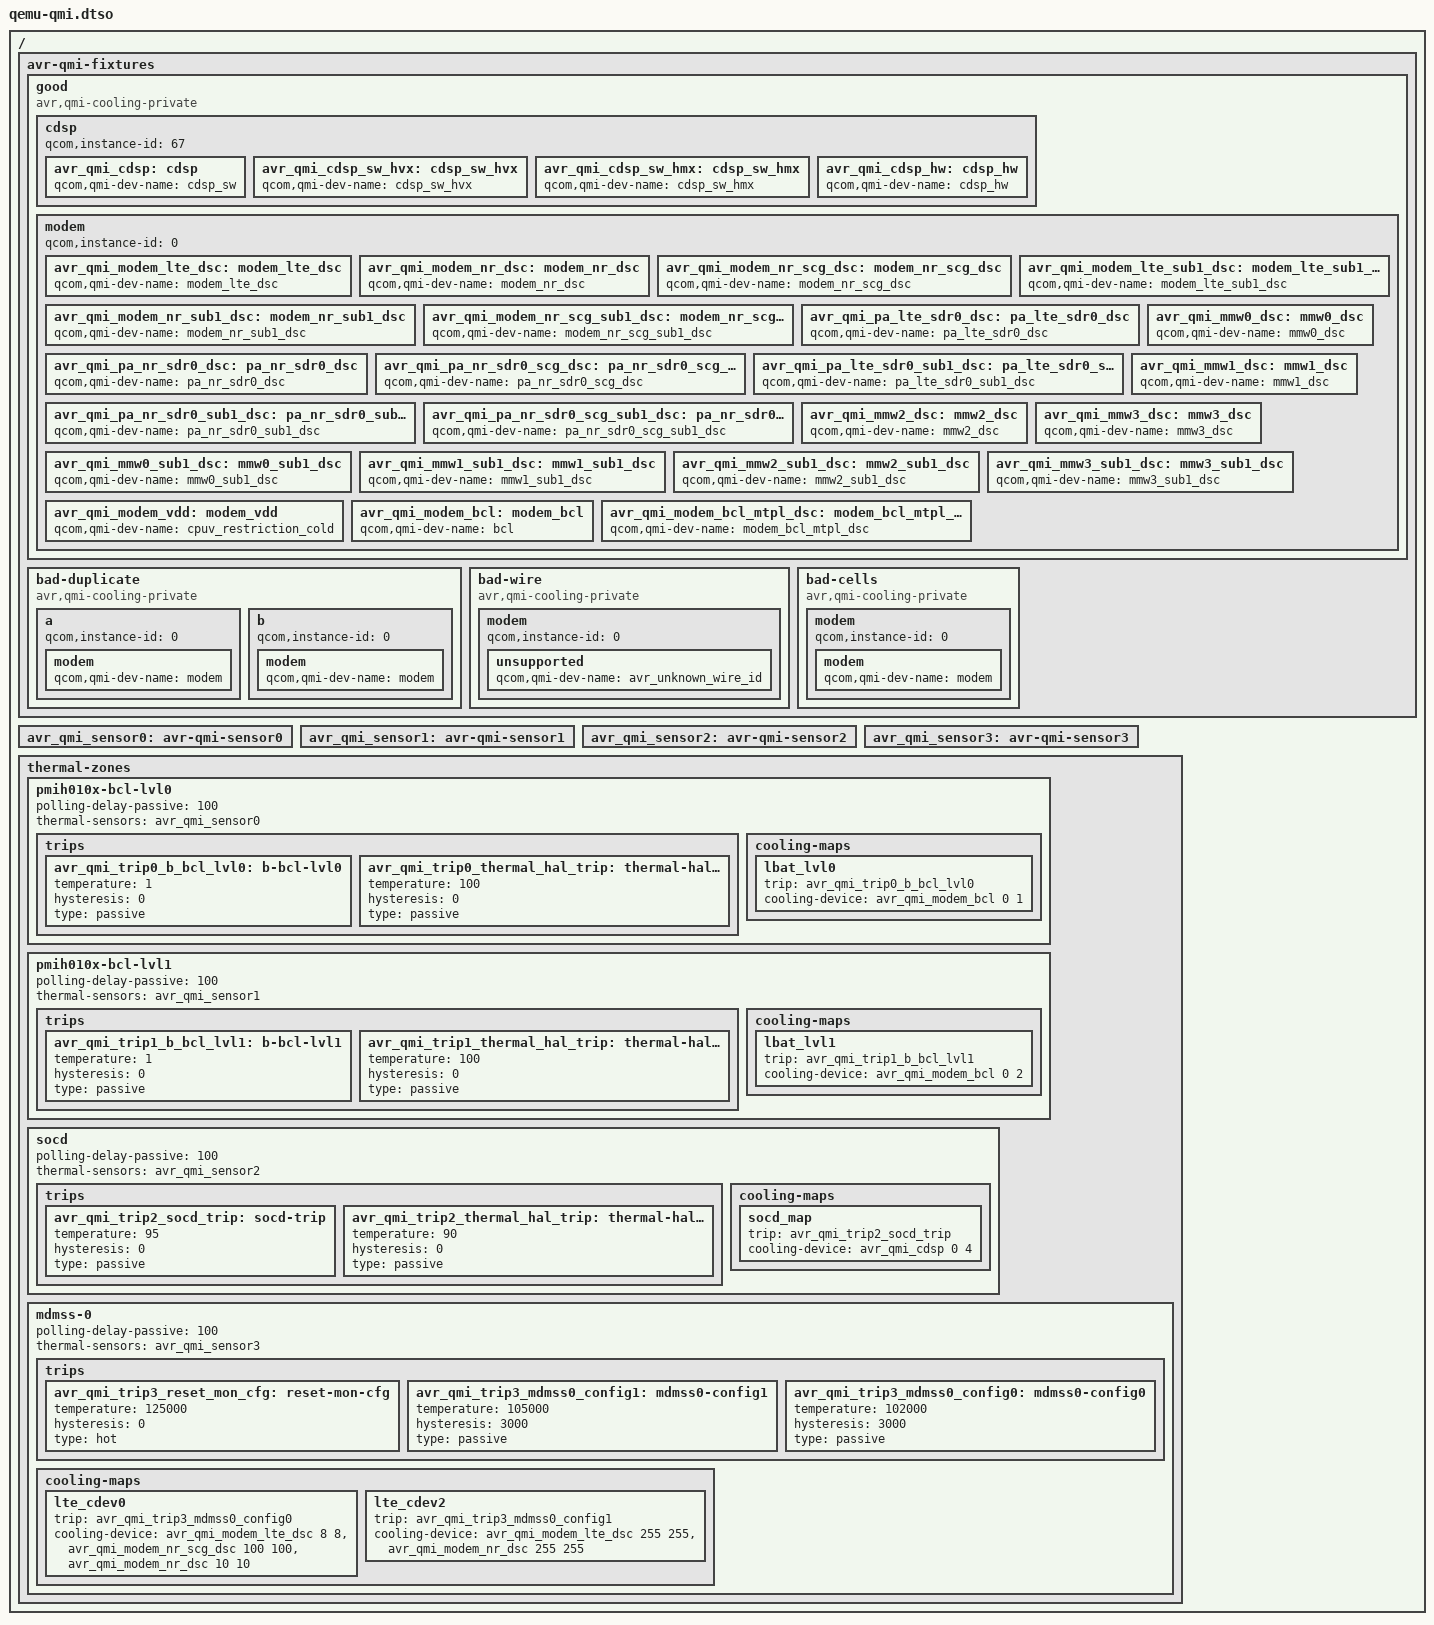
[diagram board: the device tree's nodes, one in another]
/dts-v1/;
/plugin/;
/* Private QEMU nodes; saved AVR instance IDs, names and cooling arity. */
/ { fragment@0 { target-path = "/"; __overlay__ { avr-qmi-fixtures {
 good { compatible = "avr,qmi-cooling-private";
 cdsp { qcom,instance-id = <67>;
  avr_qmi_cdsp: cdsp { qcom,qmi-dev-name = "cdsp_sw"; #cooling-cells = <2>; };
  avr_qmi_cdsp_sw_hvx: cdsp_sw_hvx { qcom,qmi-dev-name = "cdsp_sw_hvx"; #cooling-cells = <2>; };
  avr_qmi_cdsp_sw_hmx: cdsp_sw_hmx { qcom,qmi-dev-name = "cdsp_sw_hmx"; #cooling-cells = <2>; };
  avr_qmi_cdsp_hw: cdsp_hw { qcom,qmi-dev-name = "cdsp_hw"; #cooling-cells = <2>; };
 };
 modem { qcom,instance-id = <0>;
  avr_qmi_modem_lte_dsc: modem_lte_dsc { qcom,qmi-dev-name = "modem_lte_dsc"; #cooling-cells = <2>; };
  avr_qmi_modem_nr_dsc: modem_nr_dsc { qcom,qmi-dev-name = "modem_nr_dsc"; #cooling-cells = <2>; };
  avr_qmi_modem_nr_scg_dsc: modem_nr_scg_dsc { qcom,qmi-dev-name = "modem_nr_scg_dsc"; #cooling-cells = <2>; };
  avr_qmi_modem_lte_sub1_dsc: modem_lte_sub1_dsc { qcom,qmi-dev-name = "modem_lte_sub1_dsc"; #cooling-cells = <2>; };
  avr_qmi_modem_nr_sub1_dsc: modem_nr_sub1_dsc { qcom,qmi-dev-name = "modem_nr_sub1_dsc"; #cooling-cells = <2>; };
  avr_qmi_modem_nr_scg_sub1_dsc: modem_nr_scg_sub1_dsc { qcom,qmi-dev-name = "modem_nr_scg_sub1_dsc"; #cooling-cells = <2>; };
  avr_qmi_pa_lte_sdr0_dsc: pa_lte_sdr0_dsc { qcom,qmi-dev-name = "pa_lte_sdr0_dsc"; #cooling-cells = <2>; };
  avr_qmi_pa_nr_sdr0_dsc: pa_nr_sdr0_dsc { qcom,qmi-dev-name = "pa_nr_sdr0_dsc"; #cooling-cells = <2>; };
  avr_qmi_pa_nr_sdr0_scg_dsc: pa_nr_sdr0_scg_dsc { qcom,qmi-dev-name = "pa_nr_sdr0_scg_dsc"; #cooling-cells = <2>; };
  avr_qmi_pa_lte_sdr0_sub1_dsc: pa_lte_sdr0_sub1_dsc { qcom,qmi-dev-name = "pa_lte_sdr0_sub1_dsc"; #cooling-cells = <2>; };
  avr_qmi_pa_nr_sdr0_sub1_dsc: pa_nr_sdr0_sub1_dsc { qcom,qmi-dev-name = "pa_nr_sdr0_sub1_dsc"; #cooling-cells = <2>; };
  avr_qmi_pa_nr_sdr0_scg_sub1_dsc: pa_nr_sdr0_scg_sub1_dsc { qcom,qmi-dev-name = "pa_nr_sdr0_scg_sub1_dsc"; #cooling-cells = <2>; };
  avr_qmi_mmw0_dsc: mmw0_dsc { qcom,qmi-dev-name = "mmw0_dsc"; #cooling-cells = <2>; };
  avr_qmi_mmw1_dsc: mmw1_dsc { qcom,qmi-dev-name = "mmw1_dsc"; #cooling-cells = <2>; };
  avr_qmi_mmw2_dsc: mmw2_dsc { qcom,qmi-dev-name = "mmw2_dsc"; #cooling-cells = <2>; };
  avr_qmi_mmw3_dsc: mmw3_dsc { qcom,qmi-dev-name = "mmw3_dsc"; #cooling-cells = <2>; };
  avr_qmi_mmw0_sub1_dsc: mmw0_sub1_dsc { qcom,qmi-dev-name = "mmw0_sub1_dsc"; #cooling-cells = <2>; };
  avr_qmi_mmw1_sub1_dsc: mmw1_sub1_dsc { qcom,qmi-dev-name = "mmw1_sub1_dsc"; #cooling-cells = <2>; };
  avr_qmi_mmw2_sub1_dsc: mmw2_sub1_dsc { qcom,qmi-dev-name = "mmw2_sub1_dsc"; #cooling-cells = <2>; };
  avr_qmi_mmw3_sub1_dsc: mmw3_sub1_dsc { qcom,qmi-dev-name = "mmw3_sub1_dsc"; #cooling-cells = <2>; };
  avr_qmi_modem_vdd: modem_vdd { qcom,qmi-dev-name = "cpuv_restriction_cold"; #cooling-cells = <2>; };
  avr_qmi_modem_bcl: modem_bcl { qcom,qmi-dev-name = "bcl"; #cooling-cells = <2>; };
  avr_qmi_modem_bcl_mtpl_dsc: modem_bcl_mtpl_dsc { qcom,qmi-dev-name = "modem_bcl_mtpl_dsc"; #cooling-cells = <2>; };
 };
 };
 bad-duplicate { compatible = "avr,qmi-cooling-private"; a { qcom,instance-id=<0>; modem { qcom,qmi-dev-name="modem"; #cooling-cells=<2>; }; }; b { qcom,instance-id=<0>; modem { qcom,qmi-dev-name="modem"; #cooling-cells=<2>; }; }; };
 bad-wire { compatible = "avr,qmi-cooling-private"; modem { qcom,instance-id=<0>; unsupported { qcom,qmi-dev-name="avr_unknown_wire_id"; #cooling-cells=<2>; }; }; };
 bad-cells { compatible = "avr,qmi-cooling-private"; modem { qcom,instance-id=<0>; modem { qcom,qmi-dev-name="modem"; #cooling-cells=<1>; }; }; };
 };
 avr_qmi_sensor0: avr-qmi-sensor0 { #thermal-sensor-cells=<0>; };
 avr_qmi_sensor1: avr-qmi-sensor1 { #thermal-sensor-cells=<0>; };
 avr_qmi_sensor2: avr-qmi-sensor2 { #thermal-sensor-cells=<0>; };
 avr_qmi_sensor3: avr-qmi-sensor3 { #thermal-sensor-cells=<0>; };
 thermal-zones {
 pmih010x-bcl-lvl0 { polling-delay-passive=<100>; thermal-sensors=<&avr_qmi_sensor0>;
 trips {
 avr_qmi_trip0_b_bcl_lvl0: b-bcl-lvl0 { temperature=<1>; hysteresis=<0>; type="passive"; };
 avr_qmi_trip0_thermal_hal_trip: thermal-hal-trip { temperature=<100>; hysteresis=<0>; type="passive"; };
 }; cooling-maps {
 lbat_lvl0 { trip=<&avr_qmi_trip0_b_bcl_lvl0>; cooling-device=<&avr_qmi_modem_bcl 0 1>; };
 }; };
 pmih010x-bcl-lvl1 { polling-delay-passive=<100>; thermal-sensors=<&avr_qmi_sensor1>;
 trips {
 avr_qmi_trip1_b_bcl_lvl1: b-bcl-lvl1 { temperature=<1>; hysteresis=<0>; type="passive"; };
 avr_qmi_trip1_thermal_hal_trip: thermal-hal-trip { temperature=<100>; hysteresis=<0>; type="passive"; };
 }; cooling-maps {
 lbat_lvl1 { trip=<&avr_qmi_trip1_b_bcl_lvl1>; cooling-device=<&avr_qmi_modem_bcl 0 2>; };
 }; };
 socd { polling-delay-passive=<100>; thermal-sensors=<&avr_qmi_sensor2>;
 trips {
 avr_qmi_trip2_socd_trip: socd-trip { temperature=<95>; hysteresis=<0>; type="passive"; };
 avr_qmi_trip2_thermal_hal_trip: thermal-hal-trip { temperature=<90>; hysteresis=<0>; type="passive"; };
 }; cooling-maps {
 socd_map { trip=<&avr_qmi_trip2_socd_trip>; cooling-device=<&avr_qmi_cdsp 0 4>; };
 }; };
 mdmss-0 { polling-delay-passive=<100>; thermal-sensors=<&avr_qmi_sensor3>;
 trips {
 avr_qmi_trip3_reset_mon_cfg: reset-mon-cfg { temperature=<125000>; hysteresis=<0>; type="hot"; };
 avr_qmi_trip3_mdmss0_config1: mdmss0-config1 { temperature=<105000>; hysteresis=<3000>; type="passive"; };
 avr_qmi_trip3_mdmss0_config0: mdmss0-config0 { temperature=<102000>; hysteresis=<3000>; type="passive"; };
 }; cooling-maps {
 lte_cdev0 { trip=<&avr_qmi_trip3_mdmss0_config0>; cooling-device=<&avr_qmi_modem_lte_dsc 8 8>, <&avr_qmi_modem_nr_scg_dsc 100 100>, <&avr_qmi_modem_nr_dsc 10 10>; };
 lte_cdev2 { trip=<&avr_qmi_trip3_mdmss0_config1>; cooling-device=<&avr_qmi_modem_lte_dsc 255 255>, <&avr_qmi_modem_nr_dsc 255 255>; };
 }; };
 };
 }; }; };
